AUTOSAR XML (schema 4-2-2)
package /STELLANTIS/EPT/ASWCs
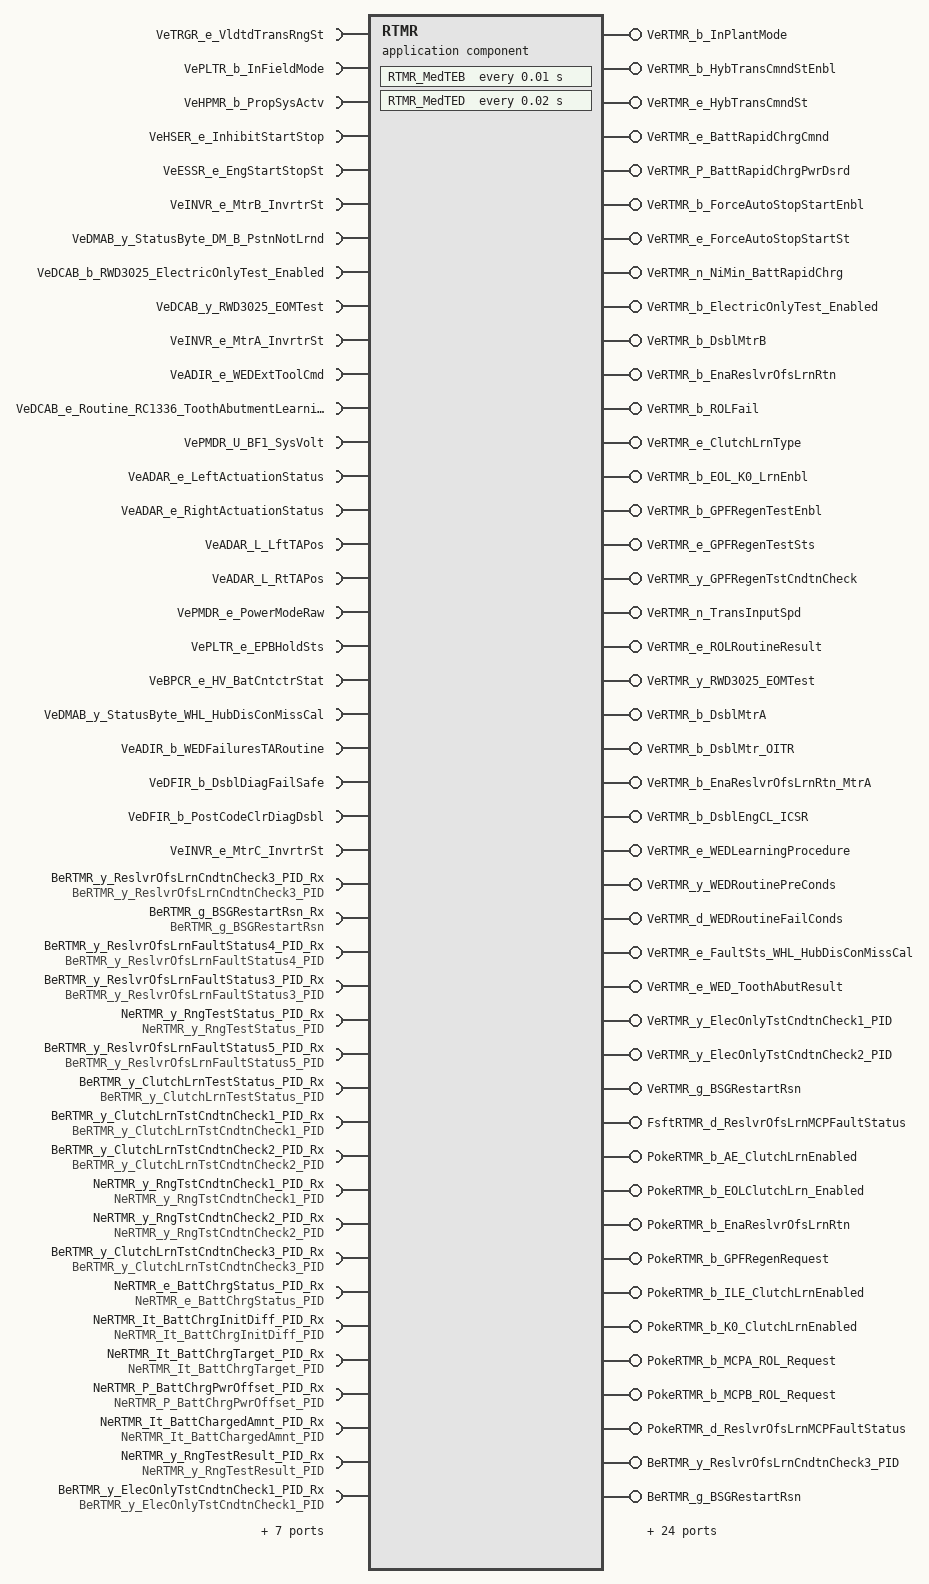
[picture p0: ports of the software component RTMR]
  application sw component type RTMR
    25 x require port:
      VeTRGR_e_VldtdTransRngSt: variation-point={short-label=vpVeTRGR_e_VldtdTransRngSt, sw-syscond=1}, nonqueued-receiver-com-spec{data-element=Value, init-value=CeTRGR_e_NoSelectionAvailable}, required-interface=VeTRGR_e_VldtdTransRngSt
      VePLTR_b_InFieldMode: nonqueued-receiver-com-spec{data-element=Value, init-value=0}, required-interface=VePLTR_b_InFieldMode
      VeHPMR_b_PropSysActv: variation-point={short-label=vpVeHPMR_b_PropSysActv, sw-syscond=1}, nonqueued-receiver-com-spec{data-element=Value, init-value=0}, required-interface=VeHPMR_b_PropSysActv
      VeHSER_e_InhibitStartStop: nonqueued-receiver-com-spec{data-element=Value, init-value=CeHSER_e_InhibitStartStop}, required-interface=VeHSER_e_InhibitStartStop
      VeESSR_e_EngStartStopSt: nonqueued-receiver-com-spec{data-element=Value, init-value=CeESSR_e_EngOff}, required-interface=VeESSR_e_EngStartStopSt
      VeINVR_e_MtrB_InvrtrSt: variation-point={short-label=vpVeINVR_e_MtrB_InvrtrSt, sw-syscond=1}, nonqueued-receiver-com-spec{data-element=Value, init-value=CeINVR_e_NormalPowerStageOff}, required-interface=VeINVR_e_MtrB_InvrtrSt
      VeDMAB_y_StatusByte_DM_B_PstnNotLrnd: nonqueued-receiver-com-spec{data-element=Value, init-value=0}, required-interface=VeDMAB_y_StatusByte_DM_B_PstnNotLrnd
      VeDCAB_b_RWD3025_ElectricOnlyTest_Enabled: nonqueued-receiver-com-spec{data-element=Value, init-value=0}, required-interface=VeDCAB_b_RWD3025_ElectricOnlyTest_Enabled
      VeDCAB_y_RWD3025_EOMTest: nonqueued-receiver-com-spec{data-element=Value, init-value=0}, required-interface=VeDCAB_y_RWD3025_EOMTest
      VeINVR_e_MtrA_InvrtrSt: variation-point={short-label=vpVeINVR_e_MtrA_InvrtrSt, sw-syscond=1}, nonqueued-receiver-com-spec{data-element=Value, init-value=CeINVR_e_NormalPowerStageOff}, required-interface=VeINVR_e_MtrA_InvrtrSt
      VeADIR_e_WEDExtToolCmd: variation-point={short-label=vpVeADIR_e_WEDExtToolCmd, sw-syscond=1}, nonqueued-receiver-com-spec{data-element=Value, init-value=CeADIR_e_ECUNormalControl}, required-interface=VeADIR_e_WEDExtToolCmd
      VeDCAB_e_Routine_RC1336_ToothAbutmentLearning_Op: nonqueued-receiver-com-spec{data-element=Value, init-value=CeDCAB_e_Routine_NOP}, required-interface=VeDCAB_e_Routine_RC1336_ToothAbutmentLearning_Op
      VePMDR_U_BF1_SysVolt: variation-point={short-label=vpVePMDR_U_BF1_SysVolt, sw-syscond=1}, nonqueued-receiver-com-spec{data-element=Value, init-value=0}, required-interface=VePMDR_U_BF1_SysVolt
      VeADAR_e_LeftActuationStatus: variation-point={short-label=vpVeADAR_e_LeftActuationStatus, sw-syscond=1}, nonqueued-receiver-com-spec{data-element=Value, init-value=CeADAR_e_SS_Indeterminate}, required-interface=VeADAR_e_LeftActuationStatus
      VeADAR_e_RightActuationStatus: variation-point={short-label=vpVeADAR_e_RightActuationStatus, sw-syscond=1}, nonqueued-receiver-com-spec{data-element=Value, init-value=CeADAR_e_SS_Indeterminate}, required-interface=VeADAR_e_RightActuationStatus
      VeADAR_L_LftTAPos: variation-point={short-label=vpVeADAR_L_LftTAPos, sw-syscond=1}, nonqueued-receiver-com-spec{data-element=Value, init-value=0}, required-interface=VeADAR_L_LftTAPos
      VeADAR_L_RtTAPos: variation-point={short-label=vpVeADAR_L_RtTAPos, sw-syscond=1}, nonqueued-receiver-com-spec{data-element=Value, init-value=0}, required-interface=VeADAR_L_RtTAPos
      VePMDR_e_PowerModeRaw: variation-point={short-label=vpVePMDR_e_PowerModeRaw, sw-syscond=1}, nonqueued-receiver-com-spec{data-element=Value, init-value=CePMDR_e_PowerMode_Off}, required-interface=VePMDR_e_PowerModeRaw
      VePLTR_e_EPBHoldSts: variation-point={short-label=vpVePLTR_e_EPBHoldSts, sw-syscond=1}, nonqueued-receiver-com-spec{data-element=Value, init-value=CePLTR_e_EPBHoldSts_REL}, required-interface=VePLTR_e_EPBHoldSts
      VeBPCR_e_HV_BatCntctrStat: variation-point={short-label=vpVeBPCR_e_HV_BatCntctrStat, sw-syscond=1}, nonqueued-receiver-com-spec{data-element=Value, init-value=CeHVTR_e_Open}, required-interface=VeBPCR_e_HV_BatCntctrStat
      VeDMAB_y_StatusByte_WHL_HubDisConMissCal: variation-point={short-label=vpVeDMAB_y_StatusByte_WHL_HubDisConMissCal, sw-syscond=1}, nonqueued-receiver-com-spec{data-element=Value, init-value=0}, required-interface=VeDMAB_y_StatusByte_WHL_HubDisConMissCal
      VeADIR_b_WEDFailuresTARoutine: variation-point={short-label=vpVeADIR_b_WEDFailuresTARoutine, sw-syscond=1}, nonqueued-receiver-com-spec{data-element=Value, init-value=0}, required-interface=VeADIR_b_WEDFailuresTARoutine
      VeDFIR_b_DsblDiagFailSafe: variation-point={short-label=vpVeDFIR_b_DsblDiagFailSafe, sw-syscond=1}, nonqueued-receiver-com-spec{data-element=Value, init-value=0}, required-interface=VeDFIR_b_DsblDiagFailSafe
      VeDFIR_b_PostCodeClrDiagDsbl: variation-point={short-label=vpVeDFIR_b_PostCodeClrDiagDsbl, sw-syscond=1}, nonqueued-receiver-com-spec{data-element=Value, init-value=0}, required-interface=VeDFIR_b_PostCodeClrDiagDsbl
      VeINVR_e_MtrC_InvrtrSt: variation-point={short-label=vpVeINVR_e_MtrC_InvrtrSt, sw-syscond=1}, nonqueued-receiver-com-spec{data-element=Value, init-value=CeINVR_e_NormalPowerStageOff}, required-interface=VeINVR_e_MtrC_InvrtrSt
    42 x provide port:
      VeRTMR_b_InPlantMode: nonqueued-sender-com-spec{data-element=Value, init-value=0}, provided-interface=VeRTMR_b_InPlantMode
      VeRTMR_b_HybTransCmndStEnbl: nonqueued-sender-com-spec{data-element=Value, init-value=0}, provided-interface=VeRTMR_b_HybTransCmndStEnbl
      VeRTMR_e_HybTransCmndSt: nonqueued-sender-com-spec{data-element=Value, init-value=CeOHSR_e_RngSel_N}, provided-interface=VeRTMR_e_HybTransCmndSt
      VeRTMR_e_BattRapidChrgCmnd: nonqueued-sender-com-spec{data-element=Value, init-value=CeRTMR_e_BattRapidChrgDisable}, provided-interface=VeRTMR_e_BattRapidChrgCmnd
      VeRTMR_P_BattRapidChrgPwrDsrd: nonqueued-sender-com-spec{data-element=Value, init-value=0}, provided-interface=VeRTMR_P_BattRapidChrgPwrDsrd
      VeRTMR_b_ForceAutoStopStartEnbl: nonqueued-sender-com-spec{data-element=Value, init-value=0}, provided-interface=VeRTMR_b_ForceAutoStopStartEnbl
      VeRTMR_e_ForceAutoStopStartSt: nonqueued-sender-com-spec{data-element=Value, init-value=CeSTRR_e_NoOvrrd}, provided-interface=VeRTMR_e_ForceAutoStopStartSt
      VeRTMR_n_NiMin_BattRapidChrg: nonqueued-sender-com-spec{data-element=Value, init-value=0}, provided-interface=VeRTMR_n_NiMin_BattRapidChrg
      VeRTMR_b_ElectricOnlyTest_Enabled: nonqueued-sender-com-spec{data-element=Value, init-value=0}, provided-interface=VeRTMR_b_ElectricOnlyTest_Enabled
      VeRTMR_b_DsblMtrB: nonqueued-sender-com-spec{data-element=Value, init-value=0}, provided-interface=VeRTMR_b_DsblMtrB
      VeRTMR_b_EnaReslvrOfsLrnRtn: nonqueued-sender-com-spec{data-element=Value, init-value=0}, provided-interface=VeRTMR_b_EnaReslvrOfsLrnRtn
      VeRTMR_b_ROLFail: nonqueued-sender-com-spec{data-element=Value, init-value=0}, provided-interface=VeRTMR_b_ROLFail
      VeRTMR_e_ClutchLrnType: nonqueued-sender-com-spec{data-element=Value, init-value=CeRTMR_e_Clutch_NoLrn}, provided-interface=VeRTMR_e_ClutchLrnType
      VeRTMR_b_EOL_K0_LrnEnbl: nonqueued-sender-com-spec{data-element=Value, init-value=0}, provided-interface=VeRTMR_b_EOL_K0_LrnEnbl
      VeRTMR_b_GPFRegenTestEnbl: nonqueued-sender-com-spec{data-element=Value, init-value=0}, provided-interface=VeRTMR_b_GPFRegenTestEnbl
      VeRTMR_e_GPFRegenTestSts: nonqueued-sender-com-spec{data-element=Value, init-value=CeRTMR_e_GPFRegenSts_Stopped}, provided-interface=VeRTMR_e_GPFRegenTestSts
      VeRTMR_y_GPFRegenTstCndtnCheck: nonqueued-sender-com-spec{data-element=Value, init-value=0}, provided-interface=VeRTMR_y_GPFRegenTstCndtnCheck
      VeRTMR_n_TransInputSpd: nonqueued-sender-com-spec{data-element=Value, init-value=0}, provided-interface=VeRTMR_n_TransInputSpd
      VeRTMR_e_ROLRoutineResult: nonqueued-sender-com-spec{data-element=Value, init-value=CeRTMR_e_ROLNotActive}, provided-interface=VeRTMR_e_ROLRoutineResult
      VeRTMR_y_RWD3025_EOMTest: nonqueued-sender-com-spec{data-element=Value, init-value=0}, provided-interface=VeRTMR_y_RWD3025_EOMTest
      VeRTMR_b_DsblMtrA: nonqueued-sender-com-spec{data-element=Value, init-value=0}, provided-interface=VeRTMR_b_DsblMtrA
      VeRTMR_b_DsblMtr_OITR: nonqueued-sender-com-spec{data-element=Value, init-value=0}, provided-interface=VeRTMR_b_DsblMtr_OITR
      VeRTMR_b_EnaReslvrOfsLrnRtn_MtrA: nonqueued-sender-com-spec{data-element=Value, init-value=0}, provided-interface=VeRTMR_b_EnaReslvrOfsLrnRtn_MtrA
      VeRTMR_b_DsblEngCL_ICSR: nonqueued-sender-com-spec{data-element=Value, init-value=0}, provided-interface=VeRTMR_b_DsblEngCL_ICSR
      VeRTMR_e_WEDLearningProcedure: nonqueued-sender-com-spec{data-element=Value, init-value=CeRTMR_e_WED_Not_Active}, provided-interface=VeRTMR_e_WEDLearningProcedure
      VeRTMR_y_WEDRoutinePreConds: nonqueued-sender-com-spec{data-element=Value, init-value=0}, provided-interface=VeRTMR_y_WEDRoutinePreConds
      VeRTMR_d_WEDRoutineFailConds: nonqueued-sender-com-spec{data-element=Value, init-value=0}, provided-interface=VeRTMR_d_WEDRoutineFailConds
      VeRTMR_e_FaultSts_WHL_HubDisConMissCal: nonqueued-sender-com-spec{data-element=Value, init-value=CeDFIB_e_Init}, provided-interface=VeRTMR_e_FaultSts_WHL_HubDisConMissCal
      VeRTMR_e_WED_ToothAbutResult: nonqueued-sender-com-spec{data-element=Value, init-value=CeRTMR_e_WED_Passed}, provided-interface=VeRTMR_e_WED_ToothAbutResult
      VeRTMR_y_ElecOnlyTstCndtnCheck1_PID: nonqueued-sender-com-spec{data-element=Value, init-value=0}, provided-interface=VeRTMR_y_ElecOnlyTstCndtnCheck1_PID
      VeRTMR_y_ElecOnlyTstCndtnCheck2_PID: nonqueued-sender-com-spec{data-element=Value, init-value=0}, provided-interface=VeRTMR_y_ElecOnlyTstCndtnCheck2_PID
      VeRTMR_g_BSGRestartRsn: nonqueued-sender-com-spec{data-element=Value, init-value=0}, provided-interface=VeRTMR_g_BSGRestartRsn
      FsftRTMR_d_ReslvrOfsLrnMCPFaultStatus: server-com-spec=FsftRTMR_d_ReslvrOfsLrnMCPFaultStatus, provided-interface=FsftRTMR_d_ReslvrOfsLrnMCPFaultStatus
      PokeRTMR_b_AE_ClutchLrnEnabled: server-com-spec{operation=PokeRTMR_b_AE_ClutchLrnEnabled, queue-length=1}, provided-interface=PokeRTMR_b_AE_ClutchLrnEnabled
      PokeRTMR_b_EOLClutchLrn_Enabled: server-com-spec{operation=PokeRTMR_b_EOLClutchLrn_Enabled, queue-length=1}, provided-interface=PokeRTMR_b_EOLClutchLrn_Enabled
      PokeRTMR_b_EnaReslvrOfsLrnRtn: server-com-spec{operation=PokeRTMR_b_EnaReslvrOfsLrnRtn, queue-length=1}, provided-interface=PokeRTMR_b_EnaReslvrOfsLrnRtn
      PokeRTMR_b_GPFRegenRequest: server-com-spec{operation=PokeRTMR_b_GPFRegenRequest, queue-length=1}, provided-interface=PokeRTMR_b_GPFRegenRequest
      PokeRTMR_b_ILE_ClutchLrnEnabled: server-com-spec{operation=PokeRTMR_b_ILE_ClutchLrnEnabled, queue-length=1}, provided-interface=PokeRTMR_b_ILE_ClutchLrnEnabled
      PokeRTMR_b_K0_ClutchLrnEnabled: server-com-spec{operation=PokeRTMR_b_K0_ClutchLrnEnabled, queue-length=1}, provided-interface=PokeRTMR_b_K0_ClutchLrnEnabled
      PokeRTMR_b_MCPA_ROL_Request: server-com-spec{operation=PokeRTMR_b_MCPA_ROL_Request, queue-length=1}, provided-interface=PokeRTMR_b_MCPA_ROL_Request
      PokeRTMR_b_MCPB_ROL_Request: server-com-spec{operation=PokeRTMR_b_MCPB_ROL_Request, queue-length=1}, provided-interface=PokeRTMR_b_MCPB_ROL_Request
      PokeRTMR_d_ReslvrOfsLrnMCPFaultStatus: server-com-spec{operation=PokeRTMR_d_ReslvrOfsLrnMCPFaultStatus, queue-length=1}, provided-interface=PokeRTMR_d_ReslvrOfsLrnMCPFaultStatus
    26 x require port:
      BeRTMR_y_ReslvrOfsLrnCndtnCheck3_PID_Rx: nv-require-com-spec{init-value=0, variable=BeRTMR_y_ReslvrOfsLrnCndtnCheck3_PID}, required-interface=BeRTMR_y_ReslvrOfsLrnCndtnCheck3_PID
      BeRTMR_g_BSGRestartRsn_Rx: nv-require-com-spec{init-value=0, variable=BeRTMR_g_BSGRestartRsn}, required-interface=BeRTMR_g_BSGRestartRsn
      BeRTMR_y_ReslvrOfsLrnFaultStatus4_PID_Rx: nv-require-com-spec{init-value=0, variable=BeRTMR_y_ReslvrOfsLrnFaultStatus4_PID}, required-interface=BeRTMR_y_ReslvrOfsLrnFaultStatus4_PID
      BeRTMR_y_ReslvrOfsLrnFaultStatus3_PID_Rx: nv-require-com-spec{init-value=0, variable=BeRTMR_y_ReslvrOfsLrnFaultStatus3_PID}, required-interface=BeRTMR_y_ReslvrOfsLrnFaultStatus3_PID
      NeRTMR_y_RngTestStatus_PID_Rx: nv-require-com-spec{init-value=0, variable=NeRTMR_y_RngTestStatus_PID}, required-interface=NeRTMR_y_RngTestStatus_PID
      BeRTMR_y_ReslvrOfsLrnFaultStatus5_PID_Rx: nv-require-com-spec{init-value=0, variable=BeRTMR_y_ReslvrOfsLrnFaultStatus5_PID}, required-interface=BeRTMR_y_ReslvrOfsLrnFaultStatus5_PID
      BeRTMR_y_ClutchLrnTestStatus_PID_Rx: nv-require-com-spec{init-value=0, variable=BeRTMR_y_ClutchLrnTestStatus_PID}, required-interface=BeRTMR_y_ClutchLrnTestStatus_PID
      BeRTMR_y_ClutchLrnTstCndtnCheck1_PID_Rx: nv-require-com-spec{init-value=0, variable=BeRTMR_y_ClutchLrnTstCndtnCheck1_PID}, required-interface=BeRTMR_y_ClutchLrnTstCndtnCheck1_PID
      BeRTMR_y_ClutchLrnTstCndtnCheck2_PID_Rx: nv-require-com-spec{init-value=0, variable=BeRTMR_y_ClutchLrnTstCndtnCheck2_PID}, required-interface=BeRTMR_y_ClutchLrnTstCndtnCheck2_PID
      NeRTMR_y_RngTstCndtnCheck1_PID_Rx: nv-require-com-spec{init-value=0, variable=NeRTMR_y_RngTstCndtnCheck1_PID}, required-interface=NeRTMR_y_RngTstCndtnCheck1_PID
      NeRTMR_y_RngTstCndtnCheck2_PID_Rx: nv-require-com-spec{init-value=0, variable=NeRTMR_y_RngTstCndtnCheck2_PID}, required-interface=NeRTMR_y_RngTstCndtnCheck2_PID
      BeRTMR_y_ClutchLrnTstCndtnCheck3_PID_Rx: nv-require-com-spec{init-value=0, variable=BeRTMR_y_ClutchLrnTstCndtnCheck3_PID}, required-interface=BeRTMR_y_ClutchLrnTstCndtnCheck3_PID
      NeRTMR_e_BattChrgStatus_PID_Rx: nv-require-com-spec{init-value=CeRTMR_e_BattChrgStatus_NotStarted, variable=NeRTMR_e_BattChrgStatus_PID}, required-interface=NeRTMR_e_BattChrgStatus_PID
      NeRTMR_It_BattChrgInitDiff_PID_Rx: nv-require-com-spec{init-value=0, variable=NeRTMR_It_BattChrgInitDiff_PID}, required-interface=NeRTMR_It_BattChrgInitDiff_PID
      NeRTMR_It_BattChrgTarget_PID_Rx: nv-require-com-spec{init-value=0, variable=NeRTMR_It_BattChrgTarget_PID}, required-interface=NeRTMR_It_BattChrgTarget_PID
      NeRTMR_P_BattChrgPwrOffset_PID_Rx: nv-require-com-spec{init-value=0, variable=NeRTMR_P_BattChrgPwrOffset_PID}, required-interface=NeRTMR_P_BattChrgPwrOffset_PID
      NeRTMR_It_BattChargedAmnt_PID_Rx: nv-require-com-spec{init-value=0, variable=NeRTMR_It_BattChargedAmnt_PID}, required-interface=NeRTMR_It_BattChargedAmnt_PID
      NeRTMR_y_RngTestResult_PID_Rx: nv-require-com-spec{init-value=0, variable=NeRTMR_y_RngTestResult_PID}, required-interface=NeRTMR_y_RngTestResult_PID
      BeRTMR_y_ElecOnlyTstCndtnCheck1_PID_Rx: nv-require-com-spec{init-value=0, variable=BeRTMR_y_ElecOnlyTstCndtnCheck1_PID}, required-interface=BeRTMR_y_ElecOnlyTstCndtnCheck1_PID
      BeRTMR_y_ElecOnlyTstCndtnCheck2_PID_Rx: nv-require-com-spec{init-value=0, variable=BeRTMR_y_ElecOnlyTstCndtnCheck2_PID}, required-interface=BeRTMR_y_ElecOnlyTstCndtnCheck2_PID
      NeRTMR_y_BattChrgCndtnCheck_PID_Rx: nv-require-com-spec{init-value=0, variable=NeRTMR_y_BattChrgCndtnCheck_PID}, required-interface=NeRTMR_y_BattChrgCndtnCheck_PID
      NeRTMR_t_BattChrgTimer_PID_Rx: nv-require-com-spec{init-value=0, variable=NeRTMR_t_BattChrgTimer_PID}, required-interface=NeRTMR_t_BattChrgTimer_PID
      AeRTMR_y_ElecOnlyTestResult_PID_Rx: nv-require-com-spec{init-value=0, variable=AeRTMR_y_ElecOnlyTestResult_PID}, required-interface=AeRTMR_y_ElecOnlyTestResult_PID
      AeRTMR_y_ElecOnlyTestStatus_PID_Rx: nv-require-com-spec{init-value=0, variable=AeRTMR_y_ElecOnlyTestStatus_PID}, required-interface=AeRTMR_y_ElecOnlyTestStatus_PID
      AeRTMR_b_ElectricOnlyTest_Enabled_Rx: nv-require-com-spec{init-value=0, variable=AeRTMR_b_ElectricOnlyTest_Enabled}, required-interface=AeRTMR_b_ElectricOnlyTest_Enabled
      AeRTMR_e_WED_ToothAbutResult_Rx: nv-require-com-spec{init-value=CeRTMR_e_WED_Passed, variable=AeRTMR_e_WED_ToothAbutResult}, required-interface=AeRTMR_e_WED_ToothAbutResult
    26 x provide port:
      BeRTMR_y_ReslvrOfsLrnCndtnCheck3_PID: nv-provide-com-spec{ram-block-init-value=0, variable=BeRTMR_y_ReslvrOfsLrnCndtnCheck3_PID}, provided-interface=BeRTMR_y_ReslvrOfsLrnCndtnCheck3_PID
      BeRTMR_g_BSGRestartRsn: nv-provide-com-spec{ram-block-init-value=0, variable=BeRTMR_g_BSGRestartRsn}, provided-interface=BeRTMR_g_BSGRestartRsn
      BeRTMR_y_ReslvrOfsLrnFaultStatus4_PID: nv-provide-com-spec{ram-block-init-value=0, variable=BeRTMR_y_ReslvrOfsLrnFaultStatus4_PID}, provided-interface=BeRTMR_y_ReslvrOfsLrnFaultStatus4_PID
      BeRTMR_y_ReslvrOfsLrnFaultStatus3_PID: nv-provide-com-spec{ram-block-init-value=0, variable=BeRTMR_y_ReslvrOfsLrnFaultStatus3_PID}, provided-interface=BeRTMR_y_ReslvrOfsLrnFaultStatus3_PID
      NeRTMR_y_RngTestStatus_PID: nv-provide-com-spec{ram-block-init-value=0, variable=NeRTMR_y_RngTestStatus_PID}, provided-interface=NeRTMR_y_RngTestStatus_PID
      BeRTMR_y_ReslvrOfsLrnFaultStatus5_PID: nv-provide-com-spec{ram-block-init-value=0, variable=BeRTMR_y_ReslvrOfsLrnFaultStatus5_PID}, provided-interface=BeRTMR_y_ReslvrOfsLrnFaultStatus5_PID
      BeRTMR_y_ClutchLrnTestStatus_PID: nv-provide-com-spec{ram-block-init-value=0, variable=BeRTMR_y_ClutchLrnTestStatus_PID}, provided-interface=BeRTMR_y_ClutchLrnTestStatus_PID
      BeRTMR_y_ClutchLrnTstCndtnCheck1_PID: nv-provide-com-spec{ram-block-init-value=0, variable=BeRTMR_y_ClutchLrnTstCndtnCheck1_PID}, provided-interface=BeRTMR_y_ClutchLrnTstCndtnCheck1_PID
      BeRTMR_y_ClutchLrnTstCndtnCheck2_PID: nv-provide-com-spec{ram-block-init-value=0, variable=BeRTMR_y_ClutchLrnTstCndtnCheck2_PID}, provided-interface=BeRTMR_y_ClutchLrnTstCndtnCheck2_PID
      NeRTMR_y_RngTstCndtnCheck1_PID: nv-provide-com-spec{ram-block-init-value=0, variable=NeRTMR_y_RngTstCndtnCheck1_PID}, provided-interface=NeRTMR_y_RngTstCndtnCheck1_PID
      NeRTMR_y_RngTstCndtnCheck2_PID: nv-provide-com-spec{ram-block-init-value=0, variable=NeRTMR_y_RngTstCndtnCheck2_PID}, provided-interface=NeRTMR_y_RngTstCndtnCheck2_PID
      BeRTMR_y_ClutchLrnTstCndtnCheck3_PID: nv-provide-com-spec{ram-block-init-value=0, variable=BeRTMR_y_ClutchLrnTstCndtnCheck3_PID}, provided-interface=BeRTMR_y_ClutchLrnTstCndtnCheck3_PID
      NeRTMR_e_BattChrgStatus_PID: nv-provide-com-spec{ram-block-init-value=CeRTMR_e_BattChrgStatus_NotStarted, variable=NeRTMR_e_BattChrgStatus_PID}, provided-interface=NeRTMR_e_BattChrgStatus_PID
      NeRTMR_It_BattChrgInitDiff_PID: nv-provide-com-spec{ram-block-init-value=0, variable=NeRTMR_It_BattChrgInitDiff_PID}, provided-interface=NeRTMR_It_BattChrgInitDiff_PID
      NeRTMR_It_BattChrgTarget_PID: nv-provide-com-spec{ram-block-init-value=0, variable=NeRTMR_It_BattChrgTarget_PID}, provided-interface=NeRTMR_It_BattChrgTarget_PID
      NeRTMR_P_BattChrgPwrOffset_PID: nv-provide-com-spec{ram-block-init-value=0, variable=NeRTMR_P_BattChrgPwrOffset_PID}, provided-interface=NeRTMR_P_BattChrgPwrOffset_PID
      NeRTMR_It_BattChargedAmnt_PID: nv-provide-com-spec{ram-block-init-value=0, variable=NeRTMR_It_BattChargedAmnt_PID}, provided-interface=NeRTMR_It_BattChargedAmnt_PID
      NeRTMR_y_RngTestResult_PID: nv-provide-com-spec{ram-block-init-value=0, variable=NeRTMR_y_RngTestResult_PID}, provided-interface=NeRTMR_y_RngTestResult_PID
      BeRTMR_y_ElecOnlyTstCndtnCheck1_PID: nv-provide-com-spec{ram-block-init-value=0, variable=BeRTMR_y_ElecOnlyTstCndtnCheck1_PID}, provided-interface=BeRTMR_y_ElecOnlyTstCndtnCheck1_PID
      BeRTMR_y_ElecOnlyTstCndtnCheck2_PID: nv-provide-com-spec{ram-block-init-value=0, variable=BeRTMR_y_ElecOnlyTstCndtnCheck2_PID}, provided-interface=BeRTMR_y_ElecOnlyTstCndtnCheck2_PID
      NeRTMR_y_BattChrgCndtnCheck_PID: nv-provide-com-spec{ram-block-init-value=0, variable=NeRTMR_y_BattChrgCndtnCheck_PID}, provided-interface=NeRTMR_y_BattChrgCndtnCheck_PID
      NeRTMR_t_BattChrgTimer_PID: nv-provide-com-spec{ram-block-init-value=0, variable=NeRTMR_t_BattChrgTimer_PID}, provided-interface=NeRTMR_t_BattChrgTimer_PID
      AeRTMR_y_ElecOnlyTestResult_PID: nv-provide-com-spec{ram-block-init-value=0, variable=AeRTMR_y_ElecOnlyTestResult_PID}, provided-interface=AeRTMR_y_ElecOnlyTestResult_PID
      AeRTMR_y_ElecOnlyTestStatus_PID: nv-provide-com-spec{ram-block-init-value=0, variable=AeRTMR_y_ElecOnlyTestStatus_PID}, provided-interface=AeRTMR_y_ElecOnlyTestStatus_PID
      AeRTMR_b_ElectricOnlyTest_Enabled: nv-provide-com-spec{ram-block-init-value=0, variable=AeRTMR_b_ElectricOnlyTest_Enabled}, provided-interface=AeRTMR_b_ElectricOnlyTest_Enabled
      AeRTMR_e_WED_ToothAbutResult: variation-point={short-label=vpAeRTMR_e_WED_ToothAbutResult, sw-syscond=1}, nv-provide-com-spec{ram-block-init-value=CeRTMR_e_WED_Passed, variable=AeRTMR_e_WED_ToothAbutResult}, provided-interface=AeRTMR_e_WED_ToothAbutResult
    behavior IB_RTMR: data-type-mapping=msADTtoIDTMapping, handle-termination-and-restart=NO-SUPPORT, included-data-type-set=data-type=[TeOHSR_e_OptRng, TeRTMR_e_ROLStatus]
      timing event Event_MedTEB: start-on-event=RTMR_MedTEB, period=0.01
      timing event Event_MedTED: start-on-event=RTMR_MedTED, period=0.02
      10 x operation invoked event:
        Event_FsftRTMR_d_ReslvrOfsLrnMCPFaultStatus: start-on-event=FsftRTMR_d_ReslvrOfsLrnMCPFaultStatus, operation=FsftRTMR_d_ReslvrOfsLrnMCPFaultStatus.FsftRTMR_d_ReslvrOfsLrnMCPFaultStatus
        Event_PokeRTMR_b_AE_ClutchLrnEnabled: start-on-event=PokeRTMR_b_AE_ClutchLrnEnabled, operation=PokeRTMR_b_AE_ClutchLrnEnabled.PokeRTMR_b_AE_ClutchLrnEnabled
        Event_PokeRTMR_b_EOLClutchLrn_Enabled: start-on-event=PokeRTMR_b_EOLClutchLrn_Enabled, operation=PokeRTMR_b_EOLClutchLrn_Enabled.PokeRTMR_b_EOLClutchLrn_Enabled
        Event_PokeRTMR_b_EnaReslvrOfsLrnRtn: start-on-event=PokeRTMR_b_EnaReslvrOfsLrnRtn, operation=PokeRTMR_b_EnaReslvrOfsLrnRtn.PokeRTMR_b_EnaReslvrOfsLrnRtn
        Event_PokeRTMR_b_GPFRegenRequest: start-on-event=PokeRTMR_b_GPFRegenRequest, operation=PokeRTMR_b_GPFRegenRequest.PokeRTMR_b_GPFRegenRequest
        Event_PokeRTMR_b_ILE_ClutchLrnEnabled: start-on-event=PokeRTMR_b_ILE_ClutchLrnEnabled, operation=PokeRTMR_b_ILE_ClutchLrnEnabled.PokeRTMR_b_ILE_ClutchLrnEnabled
        Event_PokeRTMR_b_K0_ClutchLrnEnabled: start-on-event=PokeRTMR_b_K0_ClutchLrnEnabled, operation=PokeRTMR_b_K0_ClutchLrnEnabled.PokeRTMR_b_K0_ClutchLrnEnabled
        Event_PokeRTMR_b_MCPA_ROL_Request: start-on-event=PokeRTMR_b_MCPA_ROL_Request, operation=PokeRTMR_b_MCPA_ROL_Request.PokeRTMR_b_MCPA_ROL_Request
        Event_PokeRTMR_b_MCPB_ROL_Request: start-on-event=PokeRTMR_b_MCPB_ROL_Request, operation=PokeRTMR_b_MCPB_ROL_Request.PokeRTMR_b_MCPB_ROL_Request
        Event_PokeRTMR_d_ReslvrOfsLrnMCPFaultStatus: start-on-event=PokeRTMR_d_ReslvrOfsLrnMCPFaultStatus, operation=PokeRTMR_d_ReslvrOfsLrnMCPFaultStatus.PokeRTMR_d_ReslvrOfsLrnMCPFaultStatus
      init event Event_RTMR_ac_Init: start-on-event=RTMR_ac_Init
      init event Event_PwrOn: start-on-event=RTMR_PwrOn
      init event Event_PwrOff: start-on-event=RTMR_PwrOff
      data received event Event_DidWrite_RWD3025_HCPModEnblr_RTMR: start-on-event=DidWrite_RWD3025_HCPModEnblr_RTMR, data=VeDCAB_b_RWD3025_ElectricOnlyTest_Enabled.Value
      data received event Event_Routine_RC1336_ToothAbutmentLearning: start-on-event=Routine_RC1336_ToothAbutmentLearning, data=VeDCAB_e_Routine_RC1336_ToothAbutmentLearning_Op.Value
      explicit-inter-runnable-variables:
        9 x data, all with category=VALUE, sw-calibration-access=READ-ONLY, type=Boolean, init-value=0:
          Init_ElectricOnlyTest_Enabled_write_IRV
          VeRTMR_b_EnaReslvrOfsLrnRtn_write_IRV
          VeRTMR_b_EOLClutchLrn_Enabled_write_IRV
          VeRTMR_b_AE_ClutchLrnEnabled_write_IRV
          VeRTMR_b_ILE_ClutchLrnEnabled_write_IRV
          VeRTMR_b_K0_ClutchLrnEnabled_write_IRV
          VeRTMR_b_GPFRegenRequest_write_IRV
          VeRTMR_b_MCPA_ROL_Request_write_IRV
          VeRTMR_b_MCPB_ROL_Request_write_IRV
      17 x runnable:
        RTMR_ac_Init
          data-send-points:
            9 x access:
              OUT_VeRTMR_e_HybTransCmndSt_Value: accessed-variable=VeRTMR_e_HybTransCmndSt.Value
              OUT_VeRTMR_e_BattRapidChrgCmnd_Value: accessed-variable=VeRTMR_e_BattRapidChrgCmnd.Value
              OUT_VeRTMR_e_ForceAutoStopStartSt_Value: accessed-variable=VeRTMR_e_ForceAutoStopStartSt.Value
              OUT_VeRTMR_e_ClutchLrnType_Value: accessed-variable=VeRTMR_e_ClutchLrnType.Value
              OUT_VeRTMR_e_GPFRegenTestSts_Value: accessed-variable=VeRTMR_e_GPFRegenTestSts.Value
              OUT_VeRTMR_e_ROLRoutineResult_Value: accessed-variable=VeRTMR_e_ROLRoutineResult.Value
              OUT_VeRTMR_e_WEDLearningProcedure_Value: accessed-variable=VeRTMR_e_WEDLearningProcedure.Value
              OUT_VeRTMR_e_FaultSts_WHL_HubDisConMissCal_Value: accessed-variable=VeRTMR_e_FaultSts_WHL_HubDisConMissCal.Value
              OUT_VeRTMR_e_WED_ToothAbutResult_Value: accessed-variable=VeRTMR_e_WED_ToothAbutResult.Value
        RTMR_PwrOn
          data-receive-point-by-arguments:
            26 x access:
              IN_AeRTMR_b_ElectricOnlyTest_Enabled_Rx_AeRTMR_b_ElectricOnlyTest_Enabled: accessed-variable=AeRTMR_b_ElectricOnlyTest_Enabled_Rx.AeRTMR_b_ElectricOnlyTest_Enabled
              IN_AeRTMR_e_WED_ToothAbutResult_Rx_AeRTMR_e_WED_ToothAbutResult: accessed-variable=AeRTMR_e_WED_ToothAbutResult_Rx.AeRTMR_e_WED_ToothAbutResult
              IN_AeRTMR_y_ElecOnlyTestResult_PID_Rx_AeRTMR_y_ElecOnlyTestResult_PID: accessed-variable=AeRTMR_y_ElecOnlyTestResult_PID_Rx.AeRTMR_y_ElecOnlyTestResult_PID
              IN_AeRTMR_y_ElecOnlyTestStatus_PID_Rx_AeRTMR_y_ElecOnlyTestStatus_PID: accessed-variable=AeRTMR_y_ElecOnlyTestStatus_PID_Rx.AeRTMR_y_ElecOnlyTestStatus_PID
              IN_BeRTMR_g_BSGRestartRsn_Rx_BeRTMR_g_BSGRestartRsn: accessed-variable=BeRTMR_g_BSGRestartRsn_Rx.BeRTMR_g_BSGRestartRsn
              IN_BeRTMR_y_ClutchLrnTestStatus_PID_Rx_BeRTMR_y_ClutchLrnTestStatus_PID: accessed-variable=BeRTMR_y_ClutchLrnTestStatus_PID_Rx.BeRTMR_y_ClutchLrnTestStatus_PID
              IN_BeRTMR_y_ClutchLrnTstCndtnCheck{1..3}_PID_Rx_BeRTMR_y_ClutchLrnTstCndtnCheck{1..3}_PID: accessed-variable=BeRTMR_y_ClutchLrnTstCndtnCheck{1..3}_PID_Rx.BeRTMR_y_ClutchLrnTstCndtnCheck{1..3}_PID
              IN_BeRTMR_y_ElecOnlyTstCndtnCheck1_PID_Rx_BeRTMR_y_ElecOnlyTstCndtnCheck1_PID: accessed-variable=BeRTMR_y_ElecOnlyTstCndtnCheck1_PID_Rx.BeRTMR_y_ElecOnlyTstCndtnCheck1_PID
              IN_BeRTMR_y_ElecOnlyTstCndtnCheck2_PID_Rx_BeRTMR_y_ElecOnlyTstCndtnCheck2_PID: accessed-variable=BeRTMR_y_ElecOnlyTstCndtnCheck2_PID_Rx.BeRTMR_y_ElecOnlyTstCndtnCheck2_PID
              IN_BeRTMR_y_ReslvrOfsLrnCndtnCheck3_PID_Rx_BeRTMR_y_ReslvrOfsLrnCndtnCheck3_PID: accessed-variable=BeRTMR_y_ReslvrOfsLrnCndtnCheck3_PID_Rx.BeRTMR_y_ReslvrOfsLrnCndtnCheck3_PID
              IN_BeRTMR_y_ReslvrOfsLrnFaultStatus{3..5}_PID_Rx_BeRTMR_y_ReslvrOfsLrnFaultStatus{3..5}_PID: accessed-variable=BeRTMR_y_ReslvrOfsLrnFaultStatus{3..5}_PID_Rx.BeRTMR_y_ReslvrOfsLrnFaultStatus{3..5}_PID
              IN_NeRTMR_It_BattChargedAmnt_PID_Rx_NeRTMR_It_BattChargedAmnt_PID: accessed-variable=NeRTMR_It_BattChargedAmnt_PID_Rx.NeRTMR_It_BattChargedAmnt_PID
              IN_NeRTMR_It_BattChrgInitDiff_PID_Rx_NeRTMR_It_BattChrgInitDiff_PID: accessed-variable=NeRTMR_It_BattChrgInitDiff_PID_Rx.NeRTMR_It_BattChrgInitDiff_PID
              IN_NeRTMR_It_BattChrgTarget_PID_Rx_NeRTMR_It_BattChrgTarget_PID: accessed-variable=NeRTMR_It_BattChrgTarget_PID_Rx.NeRTMR_It_BattChrgTarget_PID
              IN_NeRTMR_P_BattChrgPwrOffset_PID_Rx_NeRTMR_P_BattChrgPwrOffset_PID: accessed-variable=NeRTMR_P_BattChrgPwrOffset_PID_Rx.NeRTMR_P_BattChrgPwrOffset_PID
              IN_NeRTMR_e_BattChrgStatus_PID_Rx_NeRTMR_e_BattChrgStatus_PID: accessed-variable=NeRTMR_e_BattChrgStatus_PID_Rx.NeRTMR_e_BattChrgStatus_PID
              IN_NeRTMR_t_BattChrgTimer_PID_Rx_NeRTMR_t_BattChrgTimer_PID: accessed-variable=NeRTMR_t_BattChrgTimer_PID_Rx.NeRTMR_t_BattChrgTimer_PID
              IN_NeRTMR_y_BattChrgCndtnCheck_PID_Rx_NeRTMR_y_BattChrgCndtnCheck_PID: accessed-variable=NeRTMR_y_BattChrgCndtnCheck_PID_Rx.NeRTMR_y_BattChrgCndtnCheck_PID
              IN_NeRTMR_y_RngTestResult_PID_Rx_NeRTMR_y_RngTestResult_PID: accessed-variable=NeRTMR_y_RngTestResult_PID_Rx.NeRTMR_y_RngTestResult_PID
              IN_NeRTMR_y_RngTestStatus_PID_Rx_NeRTMR_y_RngTestStatus_PID: accessed-variable=NeRTMR_y_RngTestStatus_PID_Rx.NeRTMR_y_RngTestStatus_PID
              IN_NeRTMR_y_RngTstCndtnCheck1_PID_Rx_NeRTMR_y_RngTstCndtnCheck1_PID: accessed-variable=NeRTMR_y_RngTstCndtnCheck1_PID_Rx.NeRTMR_y_RngTstCndtnCheck1_PID
              IN_NeRTMR_y_RngTstCndtnCheck2_PID_Rx_NeRTMR_y_RngTstCndtnCheck2_PID: accessed-variable=NeRTMR_y_RngTstCndtnCheck2_PID_Rx.NeRTMR_y_RngTstCndtnCheck2_PID
          data-send-points:
            32 x access:
              OUT_VeRTMR_b_ElectricOnlyTest_Enabled_Value: accessed-variable=VeRTMR_b_ElectricOnlyTest_Enabled.Value
              OUT_VeRTMR_e_BattRapidChrgCmnd_Value: accessed-variable=VeRTMR_e_BattRapidChrgCmnd.Value
              OUT_VeRTMR_e_ClutchLrnType_Value: accessed-variable=VeRTMR_e_ClutchLrnType.Value
              OUT_VeRTMR_b_HybTransCmndStEnbl_Value: accessed-variable=VeRTMR_b_HybTransCmndStEnbl.Value
              OUT_VeRTMR_b_InPlantMode_Value: accessed-variable=VeRTMR_b_InPlantMode.Value
              OUT_VeRTMR_P_BattRapidChrgPwrDsrd_Value: accessed-variable=VeRTMR_P_BattRapidChrgPwrDsrd.Value
              OUT_VeRTMR_e_HybTransCmndSt_Value: accessed-variable=VeRTMR_e_HybTransCmndSt.Value
              OUT_VeRTMR_b_ForceAutoStopStartEnbl_Value: accessed-variable=VeRTMR_b_ForceAutoStopStartEnbl.Value
              OUT_VeRTMR_e_ForceAutoStopStartSt_Value: accessed-variable=VeRTMR_e_ForceAutoStopStartSt.Value
              OUT_VeRTMR_n_NiMin_BattRapidChrg_Value: accessed-variable=VeRTMR_n_NiMin_BattRapidChrg.Value
              OUT_VeRTMR_b_ROLFail_Value: accessed-variable=VeRTMR_b_ROLFail.Value
              OUT_VeRTMR_b_DsblMtrB_Value: accessed-variable=VeRTMR_b_DsblMtrB.Value
              OUT_VeRTMR_b_EnaReslvrOfsLrnRtn_Value: accessed-variable=VeRTMR_b_EnaReslvrOfsLrnRtn.Value
              OUT_VeRTMR_b_EOL_K0_LrnEnbl_Value: accessed-variable=VeRTMR_b_EOL_K0_LrnEnbl.Value
              OUT_VeRTMR_b_GPFRegenTestEnbl_Value: accessed-variable=VeRTMR_b_GPFRegenTestEnbl.Value
              OUT_VeRTMR_e_GPFRegenTestSts_Value: accessed-variable=VeRTMR_e_GPFRegenTestSts.Value
              OUT_VeRTMR_y_GPFRegenTstCndtnCheck_Value: accessed-variable=VeRTMR_y_GPFRegenTstCndtnCheck.Value
              OUT_VeRTMR_n_TransInputSpd_Value: accessed-variable=VeRTMR_n_TransInputSpd.Value
              OUT_VeRTMR_e_ROLRoutineResult_Value: accessed-variable=VeRTMR_e_ROLRoutineResult.Value
              OUT_VeRTMR_y_RWD3025_EOMTest_Value: accessed-variable=VeRTMR_y_RWD3025_EOMTest.Value
              OUT_VeRTMR_b_DsblMtrA_Value: accessed-variable=VeRTMR_b_DsblMtrA.Value
              OUT_VeRTMR_b_DsblMtr_OITR_Value: accessed-variable=VeRTMR_b_DsblMtr_OITR.Value
              OUT_VeRTMR_b_DsblEngCL_ICSR_Value: accessed-variable=VeRTMR_b_DsblEngCL_ICSR.Value
              OUT_VeRTMR_b_EnaReslvrOfsLrnRtn_MtrA_Value: accessed-variable=VeRTMR_b_EnaReslvrOfsLrnRtn_MtrA.Value
              OUT_VeRTMR_e_WEDLearningProcedure_Value: accessed-variable=VeRTMR_e_WEDLearningProcedure.Value
              OUT_VeRTMR_y_WEDRoutinePreConds_Value: accessed-variable=VeRTMR_y_WEDRoutinePreConds.Value
              OUT_VeRTMR_d_WEDRoutineFailConds_Value: accessed-variable=VeRTMR_d_WEDRoutineFailConds.Value
              OUT_VeRTMR_e_WED_ToothAbutResult_Value: accessed-variable=VeRTMR_e_WED_ToothAbutResult.Value
              OUT_VeRTMR_e_FaultSts_WHL_HubDisConMissCal_Value: accessed-variable=VeRTMR_e_FaultSts_WHL_HubDisConMissCal.Value
              OUT_VeRTMR_g_BSGRestartRsn_Value: accessed-variable=VeRTMR_g_BSGRestartRsn.Value
              OUT_VeRTMR_y_ElecOnlyTstCndtnCheck1_PID_Value: accessed-variable=VeRTMR_y_ElecOnlyTstCndtnCheck1_PID.Value
              OUT_VeRTMR_y_ElecOnlyTstCndtnCheck2_PID_Value: accessed-variable=VeRTMR_y_ElecOnlyTstCndtnCheck2_PID.Value
          written-local-variables:
            9 x access:
              WV_VeRTMR_b_GPFRegenRequest_write_IRV: accessed-variable=VeRTMR_b_GPFRegenRequest_write_IRV
              WV_VeRTMR_b_AE_ClutchLrnEnabled_write_IRV: accessed-variable=VeRTMR_b_AE_ClutchLrnEnabled_write_IRV
              WV_VeRTMR_b_EOLClutchLrn_Enabled_write_IRV: accessed-variable=VeRTMR_b_EOLClutchLrn_Enabled_write_IRV
              WV_Init_ElectricOnlyTest_Enabled_write_IRV: accessed-variable=Init_ElectricOnlyTest_Enabled_write_IRV
              WV_VeRTMR_b_EnaReslvrOfsLrnRtn_write_IRV: accessed-variable=VeRTMR_b_EnaReslvrOfsLrnRtn_write_IRV
              WV_VeRTMR_b_ILE_ClutchLrnEnabled_write_IRV: accessed-variable=VeRTMR_b_ILE_ClutchLrnEnabled_write_IRV
              WV_VeRTMR_b_K0_ClutchLrnEnabled_write_IRV: accessed-variable=VeRTMR_b_K0_ClutchLrnEnabled_write_IRV
              WV_VeRTMR_b_MCPA_ROL_Request_write_IRV: accessed-variable=VeRTMR_b_MCPA_ROL_Request_write_IRV
              WV_VeRTMR_b_MCPB_ROL_Request_write_IRV: accessed-variable=VeRTMR_b_MCPB_ROL_Request_write_IRV
        RTMR_MedTEB
          data-receive-point-by-arguments:
            access IN_VeESSR_e_EngStartStopSt_Value: accessed-variable=VeESSR_e_EngStartStopSt.Value
        RTMR_MedTED
          data-receive-point-by-arguments:
            22 x access:
              IN_VeADAR_L_LftTAPos_Value: accessed-variable=VeADAR_L_LftTAPos.Value, variation-point={short-label=vpIN_VeADAR_L_LftTAPos_Value, sw-syscond=1}
              IN_VeADAR_L_RtTAPos_Value: accessed-variable=VeADAR_L_RtTAPos.Value, variation-point={short-label=vpIN_VeADAR_L_RtTAPos_Value, sw-syscond=1}
              IN_VeADAR_e_LeftActuationStatus_Value: accessed-variable=VeADAR_e_LeftActuationStatus.Value, variation-point={short-label=vpIN_VeADAR_e_LeftActuationStatus_Value, sw-syscond=1}
              IN_VeADAR_e_RightActuationStatus_Value: accessed-variable=VeADAR_e_RightActuationStatus.Value, variation-point={short-label=vpIN_VeADAR_e_RightActuationStatus_Value, sw-syscond=1}
              IN_VeADIR_b_WEDFailuresTARoutine_Value: accessed-variable=VeADIR_b_WEDFailuresTARoutine.Value, variation-point={short-label=vpIN_VeADIR_b_WEDFailuresTARoutine_Value, sw-syscond=1}
              IN_VeADIR_e_WEDExtToolCmd_Value: accessed-variable=VeADIR_e_WEDExtToolCmd.Value, variation-point={short-label=vpIN_VeADIR_e_WEDExtToolCmd_Value, sw-syscond=1}
              IN_VeBPCR_e_HV_BatCntctrStat_Value: accessed-variable=VeBPCR_e_HV_BatCntctrStat.Value, variation-point={short-label=vpIN_VeBPCR_e_HV_BatCntctrStat_Value, sw-syscond=1}
              IN_VeDFIR_b_DsblDiagFailSafe_Value: accessed-variable=VeDFIR_b_DsblDiagFailSafe.Value, variation-point={short-label=vpIN_VeDFIR_b_DsblDiagFailSafe_Value, sw-syscond=1}
              IN_VeDFIR_b_PostCodeClrDiagDsbl_Value: accessed-variable=VeDFIR_b_PostCodeClrDiagDsbl.Value, variation-point={short-label=vpIN_VeDFIR_b_PostCodeClrDiagDsbl_Value, sw-syscond=1}
              IN_VeDMAB_y_StatusByte_DM_B_PstnNotLrnd_Value: accessed-variable=VeDMAB_y_StatusByte_DM_B_PstnNotLrnd.Value
              IN_VeDMAB_y_StatusByte_WHL_HubDisConMissCal_Value: accessed-variable=VeDMAB_y_StatusByte_WHL_HubDisConMissCal.Value, variation-point={short-label=vpIN_VeDMAB_y_StatusByte_WHL_HubDisConMissCal_Value, sw-syscond=1}
              IN_VeESSR_e_EngStartStopSt_Value: accessed-variable=VeESSR_e_EngStartStopSt.Value
              IN_VeHPMR_b_PropSysActv_Value: accessed-variable=VeHPMR_b_PropSysActv.Value, variation-point={short-label=vpIN_VeHPMR_b_PropSysActv_Value, sw-syscond=1}
              IN_VeHSER_e_InhibitStartStop_Value: accessed-variable=VeHSER_e_InhibitStartStop.Value
              IN_VeINVR_e_MtrA_InvrtrSt_Value: accessed-variable=VeINVR_e_MtrA_InvrtrSt.Value, variation-point={short-label=vpIN_VeINVR_e_MtrA_InvrtrSt_Value, sw-syscond=1}
              IN_VeINVR_e_MtrB_InvrtrSt_Value: accessed-variable=VeINVR_e_MtrB_InvrtrSt.Value, variation-point={short-label=vpIN_VeINVR_e_MtrB_InvrtrSt_Value, sw-syscond=1}
              IN_VeINVR_e_MtrC_InvrtrSt_Value: accessed-variable=VeINVR_e_MtrC_InvrtrSt.Value, variation-point={short-label=vpIN_VeINVR_e_MtrC_InvrtrSt_Value, sw-syscond=1}
              IN_VePLTR_b_InFieldMode_Value: accessed-variable=VePLTR_b_InFieldMode.Value
              IN_VePLTR_e_EPBHoldSts_Value: accessed-variable=VePLTR_e_EPBHoldSts.Value, variation-point={short-label=vpIN_VePLTR_e_EPBHoldSts_Value, sw-syscond=1}
              IN_VePMDR_U_BF1_SysVolt_Value: accessed-variable=VePMDR_U_BF1_SysVolt.Value, variation-point={short-label=vpIN_VePMDR_U_BF1_SysVolt_Value, sw-syscond=1}
              IN_VePMDR_e_PowerModeRaw_Value: accessed-variable=VePMDR_e_PowerModeRaw.Value, variation-point={short-label=vpIN_VePMDR_e_PowerModeRaw_Value, sw-syscond=1}
              IN_VeTRGR_e_VldtdTransRngSt_Value: accessed-variable=VeTRGR_e_VldtdTransRngSt.Value, variation-point={short-label=vpIN_VeTRGR_e_VldtdTransRngSt_Value, sw-syscond=1}
          data-send-points:
            32 x access:
              OUT_VeRTMR_b_InPlantMode_Value: accessed-variable=VeRTMR_b_InPlantMode.Value
              OUT_VeRTMR_e_BattRapidChrgCmnd_Value: accessed-variable=VeRTMR_e_BattRapidChrgCmnd.Value
              OUT_VeRTMR_P_BattRapidChrgPwrDsrd_Value: accessed-variable=VeRTMR_P_BattRapidChrgPwrDsrd.Value
              OUT_VeRTMR_n_NiMin_BattRapidChrg_Value: accessed-variable=VeRTMR_n_NiMin_BattRapidChrg.Value
              OUT_VeRTMR_b_ROLFail_Value: accessed-variable=VeRTMR_b_ROLFail.Value
              OUT_VeRTMR_b_DsblMtrB_Value: accessed-variable=VeRTMR_b_DsblMtrB.Value
              OUT_VeRTMR_b_EnaReslvrOfsLrnRtn_Value: accessed-variable=VeRTMR_b_EnaReslvrOfsLrnRtn.Value
              OUT_VeRTMR_e_ROLRoutineResult_Value: accessed-variable=VeRTMR_e_ROLRoutineResult.Value
              OUT_VeRTMR_e_ClutchLrnType_Value: accessed-variable=VeRTMR_e_ClutchLrnType.Value
              OUT_VeRTMR_b_EOL_K0_LrnEnbl_Value: accessed-variable=VeRTMR_b_EOL_K0_LrnEnbl.Value
              OUT_VeRTMR_n_TransInputSpd_Value: accessed-variable=VeRTMR_n_TransInputSpd.Value
              OUT_VeRTMR_b_HybTransCmndStEnbl_Value: accessed-variable=VeRTMR_b_HybTransCmndStEnbl.Value
              OUT_VeRTMR_e_HybTransCmndSt_Value: accessed-variable=VeRTMR_e_HybTransCmndSt.Value
              OUT_VeRTMR_b_ForceAutoStopStartEnbl_Value: accessed-variable=VeRTMR_b_ForceAutoStopStartEnbl.Value
              OUT_VeRTMR_e_ForceAutoStopStartSt_Value: accessed-variable=VeRTMR_e_ForceAutoStopStartSt.Value
              OUT_VeRTMR_b_GPFRegenTestEnbl_Value: accessed-variable=VeRTMR_b_GPFRegenTestEnbl.Value
              OUT_VeRTMR_e_GPFRegenTestSts_Value: accessed-variable=VeRTMR_e_GPFRegenTestSts.Value
              OUT_VeRTMR_y_GPFRegenTstCndtnCheck_Value: accessed-variable=VeRTMR_y_GPFRegenTstCndtnCheck.Value
              OUT_VeRTMR_y_RWD3025_EOMTest_Value: accessed-variable=VeRTMR_y_RWD3025_EOMTest.Value
              OUT_VeRTMR_b_DsblEngCL_ICSR_Value: accessed-variable=VeRTMR_b_DsblEngCL_ICSR.Value
              OUT_VeRTMR_b_EnaReslvrOfsLrnRtn_MtrA_Value: accessed-variable=VeRTMR_b_EnaReslvrOfsLrnRtn_MtrA.Value
              OUT_VeRTMR_b_DsblMtrA_Value: accessed-variable=VeRTMR_b_DsblMtrA.Value
              OUT_VeRTMR_b_DsblMtr_OITR_Value: accessed-variable=VeRTMR_b_DsblMtr_OITR.Value
              OUT_VeRTMR_e_WEDLearningProcedure_Value: accessed-variable=VeRTMR_e_WEDLearningProcedure.Value
              OUT_VeRTMR_y_WEDRoutinePreConds_Value: accessed-variable=VeRTMR_y_WEDRoutinePreConds.Value
              OUT_VeRTMR_d_WEDRoutineFailConds_Value: accessed-variable=VeRTMR_d_WEDRoutineFailConds.Value
              OUT_VeRTMR_e_FaultSts_WHL_HubDisConMissCal_Value: accessed-variable=VeRTMR_e_FaultSts_WHL_HubDisConMissCal.Value
              OUT_AeRTMR_e_WED_ToothAbutResult_AeRTMR_e_WED_ToothAbutResult: accessed-variable=AeRTMR_e_WED_ToothAbutResult.AeRTMR_e_WED_ToothAbutResult, variation-point={short-label=vpOUT_AeRTMR_e_WED_ToothAbutResult_AeRTMR_e_WED_ToothAbutResult, sw-syscond=1}
              OUT_VeRTMR_e_WED_ToothAbutResult_Value: accessed-variable=VeRTMR_e_WED_ToothAbutResult.Value
              OUT_VeRTMR_y_ElecOnlyTstCndtnCheck1_PID_Value: accessed-variable=VeRTMR_y_ElecOnlyTstCndtnCheck1_PID.Value
              OUT_VeRTMR_y_ElecOnlyTstCndtnCheck2_PID_Value: accessed-variable=VeRTMR_y_ElecOnlyTstCndtnCheck2_PID.Value
              OUT_VeRTMR_g_BSGRestartRsn_Value: accessed-variable=VeRTMR_g_BSGRestartRsn.Value
          read-local-variables:
            access RV_Init_ElectricOnlyTest_Enabled_write_IRV: accessed-variable=Init_ElectricOnlyTest_Enabled_write_IRV
            access RV_VeRTMR_b_EnaReslvrOfsLrnRtn_write_IRV: accessed-variable=VeRTMR_b_EnaReslvrOfsLrnRtn_write_IRV
            access RV_VeRTMR_b_MCPA_ROL_Request_write_IRV: accessed-variable=VeRTMR_b_MCPA_ROL_Request_write_IRV
        RTMR_PwrOff
          data-send-points:
            22 x access:
              OUT_BeRTMR_y_ReslvrOfsLrnCndtnCheck3_PID_BeRTMR_y_ReslvrOfsLrnCndtnCheck3_PID: accessed-variable=BeRTMR_y_ReslvrOfsLrnCndtnCheck3_PID.BeRTMR_y_ReslvrOfsLrnCndtnCheck3_PID
              OUT_BeRTMR_g_BSGRestartRsn_BeRTMR_g_BSGRestartRsn: accessed-variable=BeRTMR_g_BSGRestartRsn.BeRTMR_g_BSGRestartRsn
              OUT_BeRTMR_y_ReslvrOfsLrnFaultStatus4_PID_BeRTMR_y_ReslvrOfsLrnFaultStatus4_PID: accessed-variable=BeRTMR_y_ReslvrOfsLrnFaultStatus4_PID.BeRTMR_y_ReslvrOfsLrnFaultStatus4_PID
              OUT_BeRTMR_y_ReslvrOfsLrnFaultStatus3_PID_BeRTMR_y_ReslvrOfsLrnFaultStatus3_PID: accessed-variable=BeRTMR_y_ReslvrOfsLrnFaultStatus3_PID.BeRTMR_y_ReslvrOfsLrnFaultStatus3_PID
              OUT_NeRTMR_y_RngTestStatus_PID_NeRTMR_y_RngTestStatus_PID: accessed-variable=NeRTMR_y_RngTestStatus_PID.NeRTMR_y_RngTestStatus_PID
              OUT_BeRTMR_y_ReslvrOfsLrnFaultStatus5_PID_BeRTMR_y_ReslvrOfsLrnFaultStatus5_PID: accessed-variable=BeRTMR_y_ReslvrOfsLrnFaultStatus5_PID.BeRTMR_y_ReslvrOfsLrnFaultStatus5_PID
              OUT_BeRTMR_y_ClutchLrnTestStatus_PID_BeRTMR_y_ClutchLrnTestStatus_PID: accessed-variable=BeRTMR_y_ClutchLrnTestStatus_PID.BeRTMR_y_ClutchLrnTestStatus_PID
              OUT_BeRTMR_y_ClutchLrnTstCndtnCheck1_PID_BeRTMR_y_ClutchLrnTstCndtnCheck1_PID: accessed-variable=BeRTMR_y_ClutchLrnTstCndtnCheck1_PID.BeRTMR_y_ClutchLrnTstCndtnCheck1_PID
              OUT_BeRTMR_y_ClutchLrnTstCndtnCheck2_PID_BeRTMR_y_ClutchLrnTstCndtnCheck2_PID: accessed-variable=BeRTMR_y_ClutchLrnTstCndtnCheck2_PID.BeRTMR_y_ClutchLrnTstCndtnCheck2_PID
              OUT_NeRTMR_y_RngTstCndtnCheck1_PID_NeRTMR_y_RngTstCndtnCheck1_PID: accessed-variable=NeRTMR_y_RngTstCndtnCheck1_PID.NeRTMR_y_RngTstCndtnCheck1_PID
              OUT_NeRTMR_y_RngTstCndtnCheck2_PID_NeRTMR_y_RngTstCndtnCheck2_PID: accessed-variable=NeRTMR_y_RngTstCndtnCheck2_PID.NeRTMR_y_RngTstCndtnCheck2_PID
              OUT_BeRTMR_y_ClutchLrnTstCndtnCheck3_PID_BeRTMR_y_ClutchLrnTstCndtnCheck3_PID: accessed-variable=BeRTMR_y_ClutchLrnTstCndtnCheck3_PID.BeRTMR_y_ClutchLrnTstCndtnCheck3_PID
              OUT_NeRTMR_e_BattChrgStatus_PID_NeRTMR_e_BattChrgStatus_PID: accessed-variable=NeRTMR_e_BattChrgStatus_PID.NeRTMR_e_BattChrgStatus_PID
              OUT_NeRTMR_It_BattChrgInitDiff_PID_NeRTMR_It_BattChrgInitDiff_PID: accessed-variable=NeRTMR_It_BattChrgInitDiff_PID.NeRTMR_It_BattChrgInitDiff_PID
              OUT_NeRTMR_It_BattChrgTarget_PID_NeRTMR_It_BattChrgTarget_PID: accessed-variable=NeRTMR_It_BattChrgTarget_PID.NeRTMR_It_BattChrgTarget_PID
              OUT_NeRTMR_P_BattChrgPwrOffset_PID_NeRTMR_P_BattChrgPwrOffset_PID: accessed-variable=NeRTMR_P_BattChrgPwrOffset_PID.NeRTMR_P_BattChrgPwrOffset_PID
              OUT_NeRTMR_It_BattChargedAmnt_PID_NeRTMR_It_BattChargedAmnt_PID: accessed-variable=NeRTMR_It_BattChargedAmnt_PID.NeRTMR_It_BattChargedAmnt_PID
              OUT_NeRTMR_y_RngTestResult_PID_NeRTMR_y_RngTestResult_PID: accessed-variable=NeRTMR_y_RngTestResult_PID.NeRTMR_y_RngTestResult_PID
              OUT_BeRTMR_y_ElecOnlyTstCndtnCheck1_PID_BeRTMR_y_ElecOnlyTstCndtnCheck1_PID: accessed-variable=BeRTMR_y_ElecOnlyTstCndtnCheck1_PID.BeRTMR_y_ElecOnlyTstCndtnCheck1_PID
              OUT_BeRTMR_y_ElecOnlyTstCndtnCheck2_PID_BeRTMR_y_ElecOnlyTstCndtnCheck2_PID: accessed-variable=BeRTMR_y_ElecOnlyTstCndtnCheck2_PID.BeRTMR_y_ElecOnlyTstCndtnCheck2_PID
              OUT_NeRTMR_y_BattChrgCndtnCheck_PID_NeRTMR_y_BattChrgCndtnCheck_PID: accessed-variable=NeRTMR_y_BattChrgCndtnCheck_PID.NeRTMR_y_BattChrgCndtnCheck_PID
              OUT_NeRTMR_t_BattChrgTimer_PID_NeRTMR_t_BattChrgTimer_PID: accessed-variable=NeRTMR_t_BattChrgTimer_PID.NeRTMR_t_BattChrgTimer_PID
        DidWrite_RWD3025_HCPModEnblr_RTMR
          data-receive-point-by-arguments:
            access IN_VeDCAB_b_RWD3025_ElectricOnlyTest_Enabled_Value: accessed-variable=VeDCAB_b_RWD3025_ElectricOnlyTest_Enabled.Value
            access IN_VeDCAB_y_RWD3025_EOMTest_Value: accessed-variable=VeDCAB_y_RWD3025_EOMTest.Value
          data-send-points:
            4 x access:
              OUT_VeRTMR_b_ElectricOnlyTest_Enabled_Value: accessed-variable=VeRTMR_b_ElectricOnlyTest_Enabled.Value
              OUT_AeRTMR_b_ElectricOnlyTest_Enabled_AeRTMR_b_ElectricOnlyTest_Enabled: accessed-variable=AeRTMR_b_ElectricOnlyTest_Enabled.AeRTMR_b_ElectricOnlyTest_Enabled
              OUT_AeRTMR_y_ElecOnlyTestResult_PID_AeRTMR_y_ElecOnlyTestResult_PID: accessed-variable=AeRTMR_y_ElecOnlyTestResult_PID.AeRTMR_y_ElecOnlyTestResult_PID
              OUT_AeRTMR_y_ElecOnlyTestStatus_PID_AeRTMR_y_ElecOnlyTestStatus_PID: accessed-variable=AeRTMR_y_ElecOnlyTestStatus_PID.AeRTMR_y_ElecOnlyTestStatus_PID
          written-local-variables:
            access WV_Init_ElectricOnlyTest_Enabled_write_IRV: accessed-variable=Init_ElectricOnlyTest_Enabled_write_IRV
        Routine_RC1336_ToothAbutmentLearning
          data-receive-point-by-arguments:
            access IN_VeDCAB_e_Routine_RC1336_ToothAbutmentLearning_Op_Value: accessed-variable=VeDCAB_e_Routine_RC1336_ToothAbutmentLearning_Op.Value
        FsftRTMR_d_ReslvrOfsLrnMCPFaultStatus
        PokeRTMR_b_AE_ClutchLrnEnabled
        PokeRTMR_b_EOLClutchLrn_Enabled
        PokeRTMR_b_EnaReslvrOfsLrnRtn
          written-local-variables:
            access WV_VeRTMR_b_EnaReslvrOfsLrnRtn_write_IRV: accessed-variable=VeRTMR_b_EnaReslvrOfsLrnRtn_write_IRV
        PokeRTMR_b_GPFRegenRequest
        PokeRTMR_b_ILE_ClutchLrnEnabled
        PokeRTMR_b_K0_ClutchLrnEnabled
        PokeRTMR_b_MCPA_ROL_Request
          written-local-variables:
            access WV_VeRTMR_b_MCPA_ROL_Request_write_IRV: accessed-variable=VeRTMR_b_MCPA_ROL_Request_write_IRV
        PokeRTMR_b_MCPB_ROL_Request
        PokeRTMR_d_ReslvrOfsLrnMCPFaultStatus
      8 x variation point proxy, all with category=CONDITION:
        Variant_RTMR_{1..7}: condition-access=0
        Variant_RTMR_8: condition-access=1
